# K1921VG1T register map
Vendor: NIIET; Series: K1921VGx; File version: 2.8
CPU: other r0p1, little endian, MPU, FPU, 4 interrupt priority bits
Registers are 32-bit, read-write, reset 0x0 unless marked. A register's access mark holds for its fields unless they carry their own. Offsets are from the block's base; [hi:lo] are bit positions; lines under a group give offsets from that group; {n}, {i} and the like mark numbered series; 'fields as' and 'values as' point back to an identical list.

## RCU — Reset and clock unit
Base 0x50004000
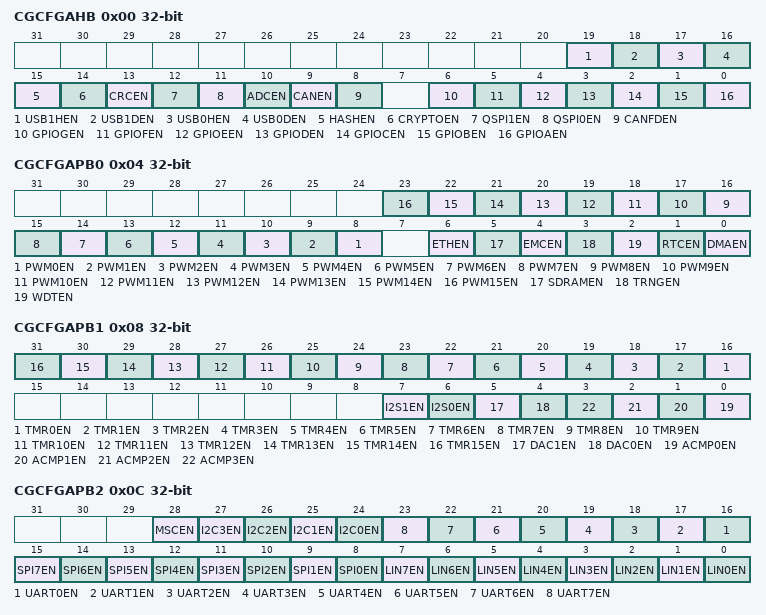
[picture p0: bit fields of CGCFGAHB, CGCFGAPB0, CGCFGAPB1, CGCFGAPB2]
0x00 CGCFGAHB — Clockgate Config AHB register
  [19] USB1HEN, [18] USB1DEN, [17] USB0HEN, [16] USB0DEN, [15] HASHEN, [14] CRYPTOEN, [13] CRCEN, [12] QSPI1EN, [11] QSPI0EN, [10] ADCEN, [9] CANEN, [8] CANFDEN, [6] GPIOGEN, [5] GPIOFEN, [4] GPIOEEN, [3] GPIODEN, [2] GPIOCEN, [1] GPIOBEN, [0] GPIOAEN
0x04 CGCFGAPB0 — Clockgate Config APB0 register
  [n+8] PWM{n}EN (n=0..15), [6] ETHEN, [5] SDRAMEN, [4] EMCEN, [3] TRNGEN, [2] WDTEN, [1] RTCEN, [0] DMAEN
0x08 CGCFGAPB1 — Clockgate Config APB1 register
  [n+16] TMR{n}EN (n=0..15), [7] I2S1EN, [6] I2S0EN, [5] DAC1EN, [4] DAC0EN, [n] ACMP{n}EN (n=0..3)
0x0C CGCFGAPB2 — Clockgate Config APB2 register
  [28] MSCEN, [n+24] I2C{n}EN (n=0..3), [n+16] UART{n}EN (n=0..7), [n+8] SPI{n}EN (n=0..7), [n] LIN{n}EN (n=0..7)
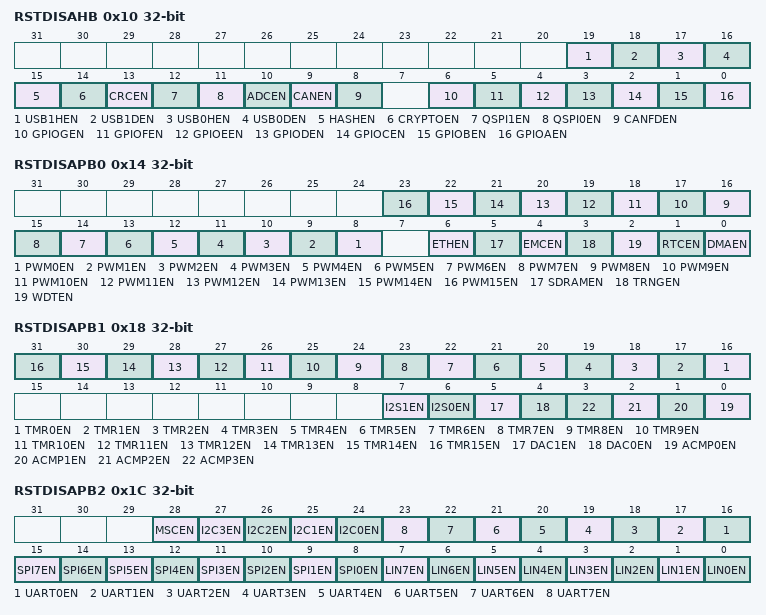
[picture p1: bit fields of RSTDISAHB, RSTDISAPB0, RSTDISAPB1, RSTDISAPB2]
0x10 RSTDISAHB — Reset Disable AHB register
  fields as CGCFGAHB
0x14 RSTDISAPB0 — Reset Disable APB0 register
  fields as CGCFGAPB0
0x18 RSTDISAPB1 — Reset Disable APB1 register
  fields as CGCFGAPB1
0x1C RSTDISAPB2 — Reset Disable APB2 register
  fields as CGCFGAPB2
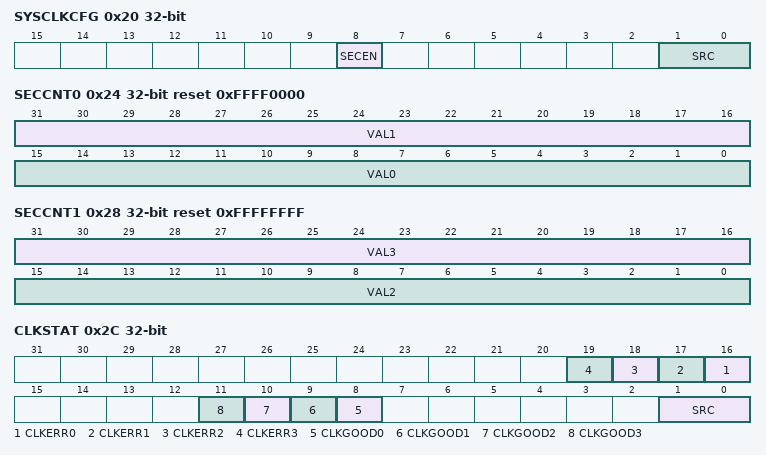
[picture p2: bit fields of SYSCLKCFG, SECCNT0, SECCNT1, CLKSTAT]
0x20 SYSCLKCFG — System clock configuration register
  [8] SECEN
  [1:0] SRC — System clock source
    0=REFCLK (HSI 4MHz if CPE=0 or HSE(XTALL) if CPE=1); 1=SRCCLK (HSE(XTALL) if CPE=0 or HSI 4MHz if CPE=1); 2=SYSPLL0CLK (Clock from PLL OUT[0]); 3=EXTCLK (external CLK from gpio pin)
0x24 SECCNT0 reset 0xFFFF0000 — Security counter configuration 0 register
  [31:16] VAL1, [15:0] VAL0 ro
0x28 SECCNT1 reset 0xFFFFFFFF — Security counter configuration 1 register
  [31:16] VAL3, [15:0] VAL2
0x2C CLKSTAT ro — System clock status register
  [n+16] CLKERR{n} (n=0..3)
  [n+8] CLKGOOD{n} (n=0..3)
  [1:0] SRC — REFCLK:0:HSI 4MHz if CPE=0 or HSE(XTALL) if CPE=1;SRCCLK:1:HSE(XTALL) if CPE=0 or HSI 4MHz if CPE=1;SYSPLL0CLK:2: Clock from PLL OUT[0];EXTCLK:3: external CLK from gpio pin;
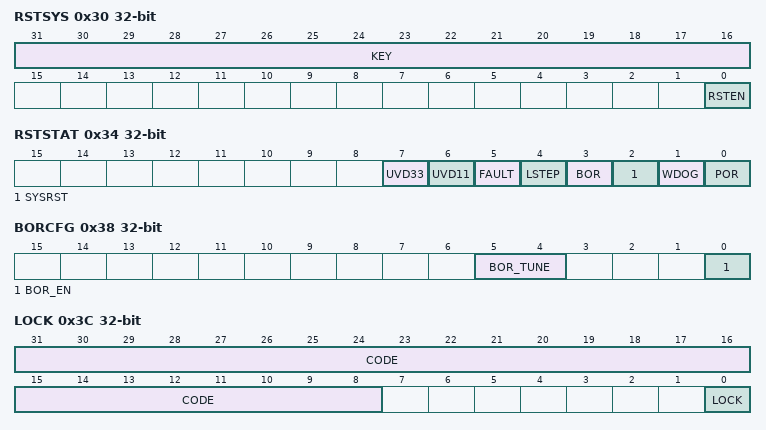
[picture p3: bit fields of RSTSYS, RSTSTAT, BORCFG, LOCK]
0x30 RSTSYS wo — System Reset Register
  [31:16] KEY — KEY 'A55A' in hexadecimal for unblocking
  [0] RSTEN — Reset enable
0x34 RSTSTAT — Reset Status Register
  [7] UVD33 — Reset due to AVDD upper voltage detect (20% up with nominal values)
  [6] UVD11 — Reset due to DVDD upper voltage detect (20% up with nominal values)
  [5] FAULT — Reset due fault timeout
  [4] LSTEP — Reset due to cores mode changing
  [3] BOR — Brown-out reset status
  [2] SYSRST — System Reset Status
  [1] WDOG — WatchDog Reset status
  [0] POR — PowerOn Reset status
0x38 BORCFG — Broun-Out Reset Configuration register
  [5:4] BOR_TUNE — Tune BOR level
  [0] BOR_EN — Enable Brown-Out reset generation
0x3C LOCK — Lock configuration register
  [31:8] CODE wo — Write key 0xACCE55 to change LOCK bit value
  [0] LOCK — Write with specific code to lock / unlock RCU registers configuration
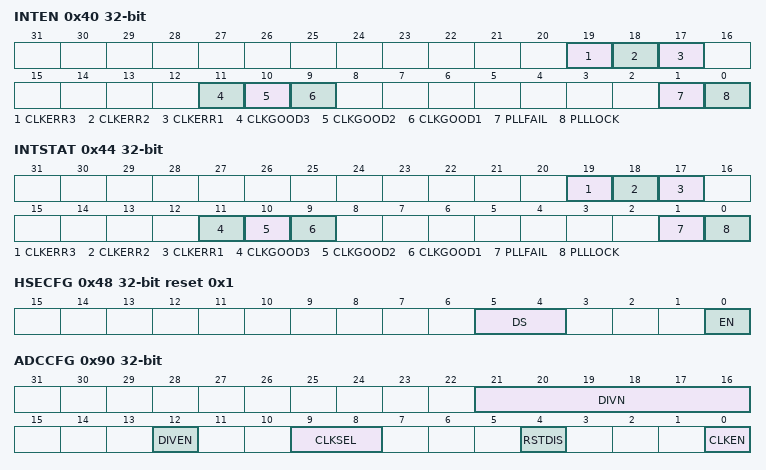
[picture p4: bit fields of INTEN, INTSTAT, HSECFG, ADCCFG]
0x40 INTEN — Interrupt enable reigster
  [19] CLKERR3
  [18] CLKERR2
  [17] CLKERR1
  [11] CLKGOOD3
  [10] CLKGOOD2
  [9] CLKGOOD1
  [1] PLLFAIL — Enable PLL fail to lock interrupt
  [0] PLLLOCK — Enable PLL lock interrupt
0x44 INTSTAT wo — Interrupt status register
  [19] CLKERR3, [18] CLKERR2, [17] CLKERR1, [11] CLKGOOD3, [10] CLKGOOD2, [9] CLKGOOD1, [1] PLLFAIL, [0] PLLLOCK
0x48 HSECFG reset 0x1 — HSE Configuration Register
  [5:4] DS — Drive current select pins
  [0] EN — Enable HSE
{0x50+4i} UARTCFG[{i}] (i=0..7) group
  0x00 VALUE — UART Clock and Reset Configuration Register
    [21:16] DIVN — Divider coefficient
    [12] DIVEN — Enable divider
    [9:8] CLKSEL — Clock source select
      values as SYSCLKCFG.SRC
    [4] RSTDIS — Reset disable
    [0] CLKEN — Clock enable
{0x70+4i} SPICFG[{i}] (i=0..7) group
  0x00 VALUE — SPI Clock and Reset Configuration Register
    fields as UARTCFG[0].VALUE
0x90 ADCCFG — ADC Clock and Reset Configuration Register
  fields as UARTCFG[0].VALUE
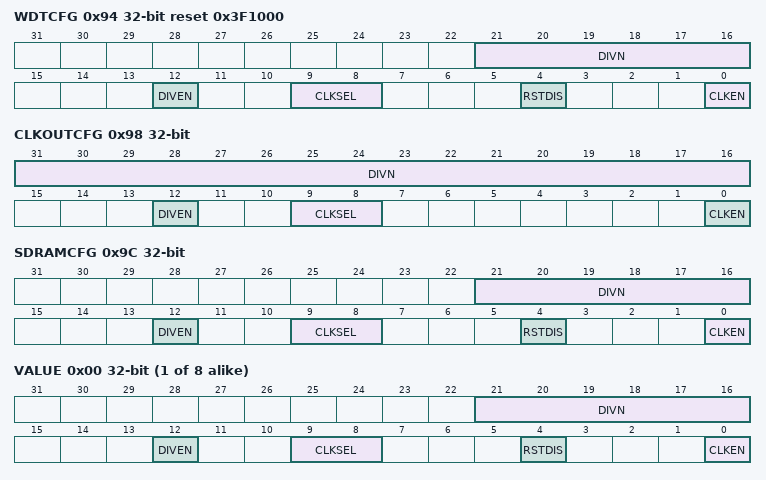
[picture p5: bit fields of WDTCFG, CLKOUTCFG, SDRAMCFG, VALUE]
0x94 WDTCFG reset 0x3F1000 — WatchDog Configuration Register
  fields as UARTCFG[0].VALUE
0x98 CLKOUTCFG — Clockout Configuration Register
  [31:16] DIVN — Divider coefficient
  [12] DIVEN — Enable divider
  [9:8] CLKSEL — Clock source select
    0=REFCLK (HSI 4MHz if CPE=0 or HSE(XTALL) if CPE=1); 1=SRCCLK (HSE(XTALL) if CPE=0 or HSI 4MHz if CPE=1); 2=SYSPLL0CLK (Clock from PLL OUT[0]); 3=LSI (32kHz oscilator)
  [0] CLKEN — Clock enable
0x9C SDRAMCFG — SDRAM Clock and Reset Configuration Register
  [21:16] DIVN — Divider coefficient
  [12] DIVEN — Enable divider
  [9:8] CLKSEL — Clock source select
    0=PLLSYSCLK (Clock from PLL OUT[0]); 1=PLL1CLK (Clock from PLL OUT[1]); 2=PLL2CLK (Clock from PLL OUT[2]); 3=EXTCLK (External clock source (GPIO))
  [4] RSTDIS — Reset active Low
  [0] CLKEN — Clock enable
{0xA0+4i} I2SCFG[{i}] (i=0..1) group
  0x00 VALUE — I2S Clock and Reset Configuration Register
    [21:16] DIVN — Divider coefficient
    [12] DIVEN — Enable divider
    [9:8] CLKSEL — Clock source select
      values as SDRAMCFG.CLKSEL
    [0] CLKEN — Clock enable
{0xB0+4i} USBCFG[{i}] (i=0..1) group
  0x00 VALUE — USB Clock and Reset Configuration Register
    fields as I2SCFG[0].VALUE
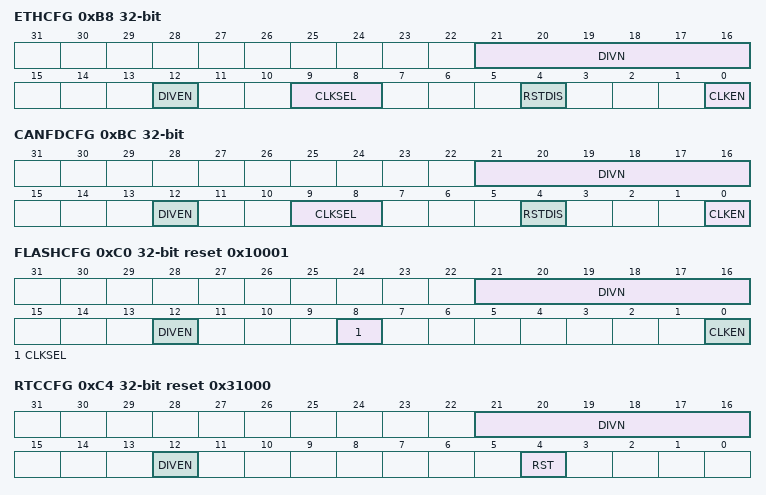
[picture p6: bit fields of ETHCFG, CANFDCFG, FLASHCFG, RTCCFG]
0xB8 ETHCFG — ETH Clock and Reset Configuration Register
  fields as SDRAMCFG
0xBC CANFDCFG — CANFD Clock and Reset Configuration Register
  fields as SDRAMCFG
0xC0 FLASHCFG reset 0x10001 — Flash Clock Configuration register
  [21:16] DIVN — Divider coefficient
  [12] DIVEN — Enable divider (depends on CPE)
  [8] CLKSEL — Clock source select (depends on CPE)
    0=REFCLK (HSI 4MHz if CPE=0 or HSE(XTALL) if CPE=1); 1=SRCCLK (HSE(XTALL) if CPE=0 or HSI 4MHz if CPE=1)
  [0] CLKEN — Clock enable
0xC4 RTCCFG reset 0x31000 — RTC APB clock divider
  [21:16] DIVN — Divider coefficient
  [12] DIVEN — Enable divider
  [4] RST — Reset active High
{0x100+0x10*i} PLL[{i}] (i=0..2) group
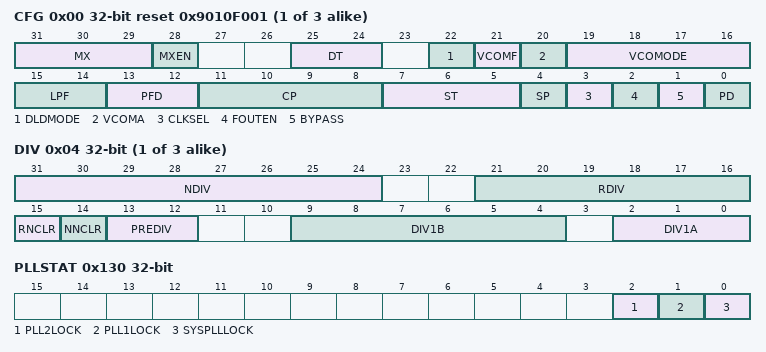
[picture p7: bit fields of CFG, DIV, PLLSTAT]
  0x00 CFG reset 0x9010F001 — PLL Configuration Register
    [31:29] MX — Test mux signal select
    [28] MXEN — Test mux enable
    [25:24] DT — Fractional noise randomization mode
    [22] DLDMODE — Frequency detector delay
    [21] VCOMF — Ajust lower range of GUN
    [20] VCOMA — Ajust amplitude of GUN
    [19:16] VCOMODE — Subband selection signal
    [15:14] LPF — Loop filter band
    [13:12] PFD — Mode of current switch
    [11:8] CP — Output current of current switch
    [7:5] ST — Sigma-delta modulator mode
    [4] SP — Song-Park mode
    [3] CLKSEL — Select reference clock
      0=HSE (HSE oscillator(src_clk)); 1=EXT (external clock from gpio)
    [2] FOUTEN — Fout enable
    [1] BYPASS — Bypass enable
    [0] PD — Powerdown enable
  0x04 DIV — PLL DIV Configuration Register
    [31:24] NDIV — Integer part of divider
    [21:16] RDIV — R-divider coefficient
    [15] RNCLR — R-divider enable
    [14] NNCLR — N-divider enable
    [13:12] PREDIV — Predivisor coefficient
    [9:4] DIV1B — Divider 1B
    [2:0] DIV1A — Divider 1A
  0x08 FRAC — PLL FRAC Configuration Register
    [23:0] FRAC — Numerator of fractional part
  0x0C MOD — PLL MOD Configuration Register
    [23:0] MOD — Denominator of fractional part
0x130 PLLSTAT ro — PLLs status regisoter
  [2] PLL2LOCK, [1] PLL1LOCK, [0] SYSPLLLOCK
